# flash register map
Vendor: Texas Instruments
Peripheral module from a debugger description file (folder sc4cc231e6pm).
Registers are 32-bit, read-write, no defined reset value unless marked. A register's access mark holds for its fields unless they carry their own. Offsets are as the file gives them; lines under a group give offsets from that group; [hi:lo] are bit positions; {n}, {i} and the like mark numbered series; 'fields as' and 'values as' point back to an identical list; <NAME> marks a mode.

## FLASH_CTRL — FLASH register offsets
0x00 FLASH_FMA — Flash Memory Address
  [16:0] FLASH_FMA_OFFSET — Address Offset
0x04 FLASH_FMD — Flash Memory Data
  [31:0] FLASH_FMD_DATA — Data Value
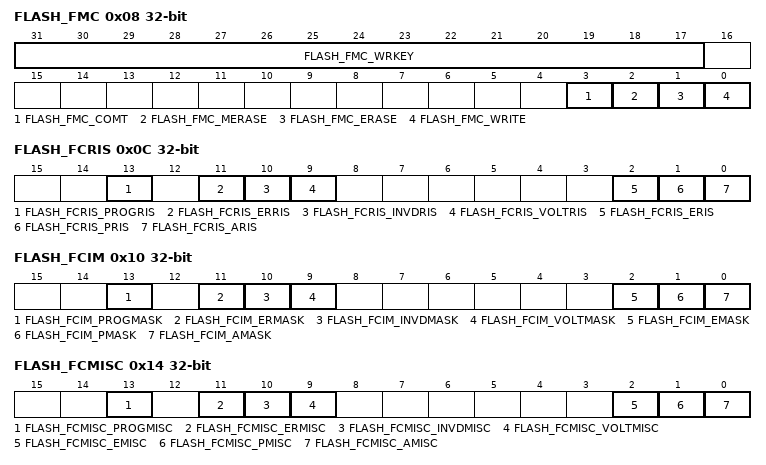
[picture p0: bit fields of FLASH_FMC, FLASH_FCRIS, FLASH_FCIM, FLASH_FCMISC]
0x08 FLASH_FMC — Flash Memory Control
  [31:17] FLASH_FMC_WRKEY — FLASH write key
  [3] FLASH_FMC_COMT — Commit Register Value
  [2] FLASH_FMC_MERASE — Mass Erase Flash Memory
  [1] FLASH_FMC_ERASE — Erase a Page of Flash Memory
  [0] FLASH_FMC_WRITE — Write a Word into Flash Memory
0x0C FLASH_FCRIS ro — Flash Controller Raw Interrupt Status
  [13] FLASH_FCRIS_PROGRIS — Program Verify Error Raw Interrupt Status
  [11] FLASH_FCRIS_ERRIS — Erase Verify Error Raw Interrupt Status
  [10] FLASH_FCRIS_INVDRIS — Invalid Data Raw Interrupt Status
  [9] FLASH_FCRIS_VOLTRIS — Pump Voltage Raw Interrupt Status
  [2] FLASH_FCRIS_ERIS — EEPROM Raw Interrupt Status
  [1] FLASH_FCRIS_PRIS — Programming Raw Interrupt Status
  [0] FLASH_FCRIS_ARIS — Access Raw Interrupt Status
0x10 FLASH_FCIM — Flash Controller Interrupt Mask
  [13] FLASH_FCIM_PROGMASK — PROGVER Interrupt Mask
  [11] FLASH_FCIM_ERMASK — ERVER Interrupt Mask
  [10] FLASH_FCIM_INVDMASK — Invalid Data Interrupt Mask
  [9] FLASH_FCIM_VOLTMASK — VOLT Interrupt Mask
  [2] FLASH_FCIM_EMASK — EEPROM Interrupt Mask
  [1] FLASH_FCIM_PMASK — Programming Interrupt Mask
  [0] FLASH_FCIM_AMASK — Access Interrupt Mask
0x14 FLASH_FCMISC — Flash Controller Masked Interrupt Status and Clear
  [13] FLASH_FCMISC_PROGMISC — PROGVER Masked Interrupt Status and Clear
  [11] FLASH_FCMISC_ERMISC — ERVER Masked Interrupt Status and Clear
  [10] FLASH_FCMISC_INVDMISC — Invalid Data Masked Interrupt Status and Clear
  [9] FLASH_FCMISC_VOLTMISC — VOLT Masked Interrupt Status and Clear
  [2] FLASH_FCMISC_EMISC — EEPROM Masked Interrupt Status and Clear
  [1] FLASH_FCMISC_PMISC — Programming Masked Interrupt Status and Clear
  [0] FLASH_FCMISC_AMISC — Access Masked Interrupt Status and Clear
0x20 FLASH_FMC2 — Flash Memory Control 2
  [0] FLASH_FMC2_WRBUF — Buffered Flash Memory Write
0x30 FLASH_FWBVAL — Flash Write Buffer Valid
  [31:0] FLASH_FWBVAL_FWB — Flash Memory Write Buffer
0x100 FLASH_FWBN — Flash Write Buffer n
  [31:0] FLASH_FWBN_DATA — Data
0xFC0 FLASH_FSIZE ro — Flash Size
  [15:0] FLASH_FSIZE_SIZE
    63=FLASH_FSIZE_SIZE_128KB (128 KB of Flash)
0xFC4 FLASH_SSIZE ro — SRAM Size
  [15:0] FLASH_SSIZE_SIZE
    127=FLASH_SSIZE_SIZE_32KB (32 KB of SRAM)
0xFCC FLASH_ROMSWMAP ro — ROM Software Map
  [0] FLASH_ROMSWMAP_SAFERTOS — SafeRTOS Present
0x10F0 FLASH_RMCTL — ROM Control
  [0] FLASH_RMCTL_BA — Boot Alias
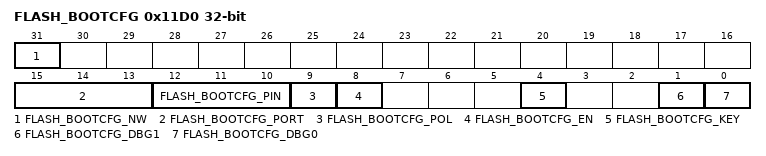
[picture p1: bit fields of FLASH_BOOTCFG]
0x11D0 FLASH_BOOTCFG ro — Boot Configuration
  [31] FLASH_BOOTCFG_NW — Not Written
  [15:13] FLASH_BOOTCFG_PORT — Boot GPIO Port
    0=FLASH_BOOTCFG_PORT_A (Port A); 1=FLASH_BOOTCFG_PORT_B (Port B); 2=FLASH_BOOTCFG_PORT_C (Port C); 3=FLASH_BOOTCFG_PORT_D (Port D); 4=FLASH_BOOTCFG_PORT_E (Port E); 5=FLASH_BOOTCFG_PORT_F (Port F); 6=FLASH_BOOTCFG_PORT_G (Port G); 7=FLASH_BOOTCFG_PORT_H (Port H)
  [12:10] FLASH_BOOTCFG_PIN — Boot GPIO Pin
    {v}=Pin {v} (v=0..7)
  [9] FLASH_BOOTCFG_POL — Boot GPIO Polarity
  [8] FLASH_BOOTCFG_EN — Boot GPIO Enable
  [4] FLASH_BOOTCFG_KEY — KEY Select
  [1] FLASH_BOOTCFG_DBG1 — Debug Control 1
  [0] FLASH_BOOTCFG_DBG0 — Debug Control 0
{0x11E0+4i} FLASH_USERREG{i} (i=0..3) — User Register {i}
  [31:0] FLASH_USERREG{i}_DATA — User Data
0x1200 FLASH_FMPRE0 access not given — Flash Memory Protection Read Enable 0
0x1204 FLASH_FMPRE1 access not given — Flash Memory Protection Read Enable 1
0x1400 FLASH_FMPPE0 access not given — Flash Memory Protection Program Enable 0
0x1404 FLASH_FMPPE1 access not given — Flash Memory Protection Program Enable 1
